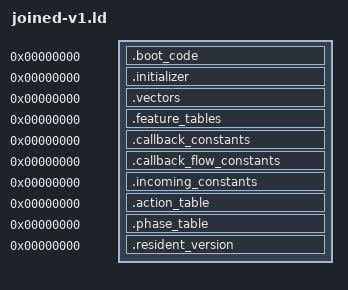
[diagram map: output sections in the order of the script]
OUTPUT_ARCH(riscv)
SECTIONS
{
 .boot_code 0 : SUBALIGN(2) { *(.boot_code)
  *(.text.tsl9_resident_startup_provider_1979a)
  *(.text.tsl9_resident_startup_block_197b0)
  *(.text.tsl9_resident_startup_provider_197b8)
  *(.text.tsl9_resident_startup_provider_197be)
  *(.text.tsl9_resident_startup_block_197cc)
  *(.text.tsl9_resident_startup_block_197d2)
  *(.text.tsl9_resident_startup_block_197dc)
  *(.text.tsl9_resident_startup_block_197e0)
  *(.text.tsl9_resident_startup_block_197e6)
  *(.text.tsl9_resident_startup_provider_197f0)
  *(.text.tsl9_resident_startup_block_19818)
  *(.text.tsl9_resident_startup_block_19872)
  *(.text.tsl9_resident_startup_block_19878)
  *(.text.tsl9_resident_startup_block_1987e)
  *(.text.tsl9_resident_startup_block_1989a)
  *(.text.tsl9_resident_startup_block_198a2)
  *(.text.tsl9_resident_startup_block_198aa)
  *(.text.tsl9_resident_startup_block_198b0)
  *(.text.tsl9_resident_startup_block_198bc)
  *(.text.tsl9_resident_startup_block_198c4)
  *(.text.tsl9_resident_startup_block_198c6)
  *(.text.tsl9_resident_startup_block_198ce)
  *(.text.tsl9_resident_startup_block_198d8)
  *(.text.tsl9_resident_startup_block_198e0)
  *(.text.tsl9_resident_startup_block_198ea)
  *(.text.tsl9_resident_startup_provider_1995c)
  *(.text.tsl9_resident_startup_block_19970)
  *(.text.tsl9_resident_startup_block_19978)
  *(.text.tsl9_resident_startup_block_1997a)
  *(.text.tsl9_resident_startup_block_1997e)
  *(.text.tsl9_resident_startup_block_19980)
  *(.text.tsl9_resident_startup_block_19982)
  *(.text.tsl9_resident_startup_block_1998c)
  *(.text.tsl9_resident_startup_block_19996)
  *(.text.tsl9_resident_startup_block_1999e)
  *(.text.tsl9_resident_startup_block_199a8)
  *(.text.tsl9_resident_startup_block_199ac)
  *(.text.tsl9_resident_startup_block_199be)
  *(.text.tsl9_resident_startup_block_199c2)
  *(.text.tsl9_resident_startup_block_199cc)
  *(.text.tsl9_resident_startup_block_199de)
  *(.text.tsl9_main_runtime_external_199e2)
  *(.text.tsl9_resident_startup_block_19a06)
  *(.text.tsl9_resident_startup_block_19a08)
  *(.text.tsl9_resident_startup_block_19a0a)
  *(.text.tsl9_resident_startup_block_19a3a)
  *(.text.tsl9_resident_startup_block_19ab8)
  *(.text.tsl9_resident_startup_block_19abe)
  *(.text.tsl9_resident_startup_block_19ad2)
  *(.text.tsl9_resident_startup_block_19ad6)
  *(.text.tsl9_resident_startup_block_19ae0)
  *(.text.tsl9_resident_startup_block_19ae2)
  *(.text.tsl9_resident_startup_block_19aee)
  *(.text.tsl9_resident_startup_block_19af0)
  *(.text.tsl9_resident_startup_block_19af2)
  *(.text.tsl9_resident_startup_block_19afc)
  *(.text.tsl9_main_runtime_external_19b16)
  *(.text.tsl9_resident_startup_block_19b30)
  *(.text.tsl9_resident_startup_block_19b3a)
  *(.text.tsl9_resident_startup_provider_19b56)
  *(.text.tsl9_resident_startup_block_19b6c)
  *(.text.tsl9_resident_startup_block_19b72)
  *(.text.tsl9_resident_startup_block_19b78)
  *(.text.tsl9_resident_startup_block_19b7e)
  *(.text.tsl9_resident_startup_block_19b86)
  *(.text.tsl9_resident_startup_block_19b8c)
  *(.text.tsl9_resident_startup_block_19b90)
  *(.text.tsl9_resident_startup_block_19b94)
  *(.text.tsl9_resident_startup_block_19b9a)
  *(.text.tsl9_resident_startup_block_19b9e)
  *(.text.tsl9_resident_startup_block_19ba4)
  *(.text.tsl9_resident_startup_block_19ba8)
  *(.text.tsl9_resident_startup_block_19bac)
  *(.text.tsl9_resident_startup_block_19bce)
 }
 .initializer 0 : SUBALIGN(4) { *(.initializer) }
 .vectors 0 : SUBALIGN(4) { *(.vectors) }
 .feature_tables 0 : SUBALIGN(4) { *(.feature_tables) }
 .callback_constants 0 : SUBALIGN(4) { *(.callback_constants) }
 .callback_flow_constants 0 : SUBALIGN(4) { *(.callback_flow_constants) }
 .incoming_constants 0 : SUBALIGN(4) { *(.incoming_constants) }
 .action_table 0 : SUBALIGN(4) { *(.action_table) }
 .phase_table 0 : SUBALIGN(4) { *(.phase_table) }
 .resident_version 0 : SUBALIGN(4) { *(.rodata.tsl9_resident_version_1ab1c) }
 /DISCARD/ : { *(.comment) *(.riscv.attributes) *(.llvm_addrsig) }
}
